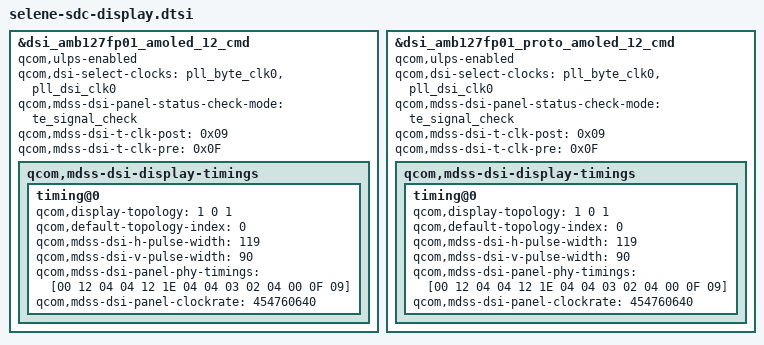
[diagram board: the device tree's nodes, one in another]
// SPDX-License-Identifier: GPL-2.0

#include <dt-bindings/clock/qcom,dispcc-monaco.h>
#include "dsi-panel-amb127fp01-amoled-cmd.dtsi"
#include "dsi-panel-amb127fp01-proto-amoled-cmd.dtsi"

&dsi_amb127fp01_amoled_12_cmd {
	qcom,ulps-enabled;
	qcom,dsi-select-clocks = "pll_byte_clk0", "pll_dsi_clk0";
	qcom,mdss-dsi-panel-status-check-mode = "te_signal_check";

	qcom,mdss-dsi-t-clk-post = <0x09>;
	qcom,mdss-dsi-t-clk-pre = <0x0F>;

	qcom,mdss-dsi-display-timings {
		timing@0 {
			qcom,display-topology = <1 0 1>;
			qcom,default-topology-index = <0>;

			qcom,mdss-dsi-h-pulse-width = <119>;
			qcom,mdss-dsi-v-pulse-width = <90>;
			qcom,mdss-dsi-panel-phy-timings = [00 12 04 04 12 1E 04
				04 03 02 04 00 0F 09];
			qcom,mdss-dsi-panel-clockrate = <454760640>;
		};
	};
};

&dsi_amb127fp01_proto_amoled_12_cmd {
	qcom,ulps-enabled;
	qcom,dsi-select-clocks = "pll_byte_clk0", "pll_dsi_clk0";

	qcom,mdss-dsi-panel-status-check-mode = "te_signal_check";
	/*
	 * TODO: b/267644923: ESD te_signal_check is not supported anymore,
	 * so ESD checking is temporarily disabled.
	 */
	//qcom,esd-check-enabled;

	qcom,mdss-dsi-t-clk-post = <0x09>;
	qcom,mdss-dsi-t-clk-pre = <0x0F>;

	qcom,mdss-dsi-display-timings {
		timing@0 {
			qcom,display-topology = <1 0 1>;
			qcom,default-topology-index = <0>;

			qcom,mdss-dsi-h-pulse-width = <119>;
			qcom,mdss-dsi-v-pulse-width = <90>;
			qcom,mdss-dsi-panel-phy-timings = [00 12 04 04 12 1E 04
				04 03 02 04 00 0F 09];
			qcom,mdss-dsi-panel-clockrate = <454760640>;
		};
	};
};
